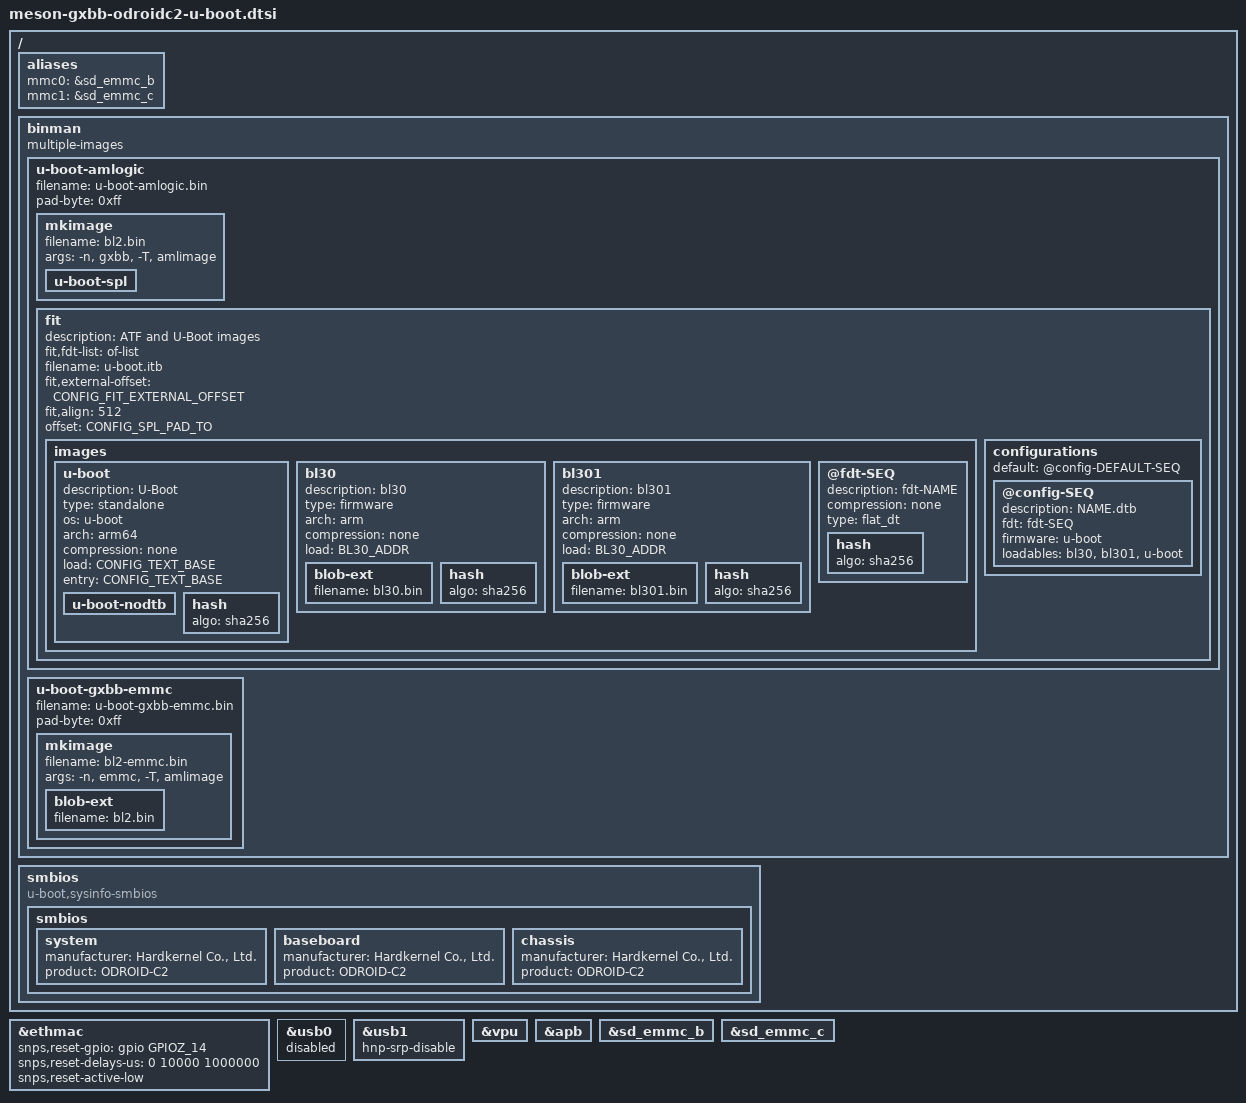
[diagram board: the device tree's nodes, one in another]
// SPDX-License-Identifier: (GPL-2.0+ OR MIT)
/*
 * Copyright (c) 2019 BayLibre, SAS.
 * Author: Neil Armstrong <narmstrong@baylibre.com>
 */

#include "meson-gx-u-boot.dtsi"

/ {
	aliases {
                mmc0 = &sd_emmc_b;
                mmc1 = &sd_emmc_c;
        };

	binman: binman {
		multiple-images;
	};

	smbios {
		compatible = "u-boot,sysinfo-smbios";

		smbios {
			system {
				manufacturer = "Hardkernel Co., Ltd.";
				product = "ODROID-C2";
			};

			baseboard {
				manufacturer = "Hardkernel Co., Ltd.";
				product = "ODROID-C2";
			};

			chassis {
				manufacturer = "Hardkernel Co., Ltd.";
				product = "ODROID-C2";
			};
		};
	};
};

&ethmac {
	snps,reset-gpio = <&gpio GPIOZ_14 0>;
	snps,reset-delays-us = <0 10000 1000000>;
	snps,reset-active-low;
};

&usb0 {
	status = "disabled";
};

&usb1 {
	hnp-srp-disable;
};

&vpu {
	/delete-property/ bootph-all;
};

&apb {
	bootph-all;
};

&sd_emmc_b {
	bootph-all;
};

&sd_emmc_c {
	bootph-all;
};

#define BL30_ADDR 0x10000000

&binman {
	u-boot-amlogic {
		filename = "u-boot-amlogic.bin";
		pad-byte = <0xff>;

		mkimage {
			filename = "bl2.bin";
			args = "-n", "gxbb", "-T", "amlimage";

			u-boot-spl {
			};
		};

		fit: fit {
			description = "ATF and U-Boot images";
			#address-cells = <1>;
			fit,fdt-list = "of-list";
			filename = "u-boot.itb";
			fit,external-offset = <CONFIG_FIT_EXTERNAL_OFFSET>;
			fit,align = <512>;
			offset = <CONFIG_SPL_PAD_TO>;

			images {
				u-boot {
					description = "U-Boot";
					type = "standalone";
					os = "u-boot";
					arch = "arm64";
					compression = "none";
					load = <CONFIG_TEXT_BASE>;
					entry = <CONFIG_TEXT_BASE>;

					u-boot-nodtb {
					};
					hash {
						algo = "sha256";
					};
				};

				bl30 {
					description = "bl30";
					type = "firmware";
					arch = "arm";
					compression = "none";
					load = <BL30_ADDR>;

					blob-ext {
						filename = "bl30.bin";
					};
					hash {
						algo = "sha256";
					};
				};

				bl301 {
					description = "bl301";
					type = "firmware";
					arch = "arm";
					compression = "none";
					load = <BL30_ADDR>;

					blob-ext {
						filename = "bl301.bin";
					};
					hash {
						algo = "sha256";
					};
				};

				@fdt-SEQ {
					description = "fdt-NAME";
					compression = "none";
					type = "flat_dt";

					hash {
						algo = "sha256";
					};
				};

			};

			configurations {
				default = "@config-DEFAULT-SEQ";
				@config-SEQ {
					description = "NAME.dtb";
					fdt = "fdt-SEQ";
					firmware = "u-boot";
					loadables = "bl30", "bl301", "u-boot";
				};
			};
		};
	};

	u-boot-gxbb-emmc {
		filename = "u-boot-gxbb-emmc.bin";
		pad-byte = <0xff>;

		mkimage {
			filename = "bl2-emmc.bin";
			args = "-n", "emmc", "-T", "amlimage";

			blob-ext {
				filename = "bl2.bin";
			};
		};
	};
};
